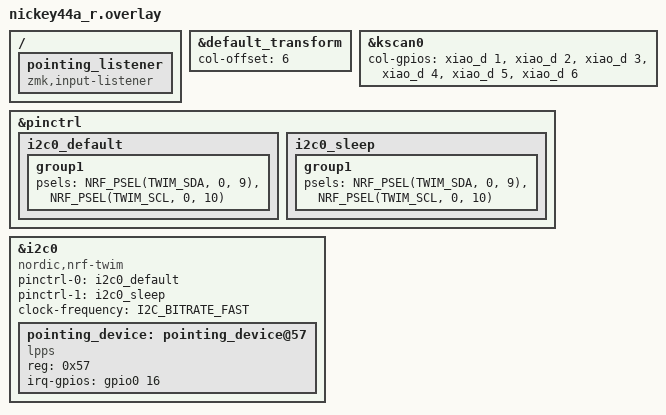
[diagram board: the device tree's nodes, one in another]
#include "nickey44a.dtsi"

&default_transform {
    col-offset = <6>;
};

&kscan0 {
        col-gpios
            = <&xiao_d 1 GPIO_ACTIVE_HIGH>
            , <&xiao_d 2 GPIO_ACTIVE_HIGH>
            , <&xiao_d 3 GPIO_ACTIVE_HIGH>
            , <&xiao_d 4 GPIO_ACTIVE_HIGH>
            , <&xiao_d 5 GPIO_ACTIVE_HIGH>
            , <&xiao_d 6 GPIO_ACTIVE_HIGH>
            ;
};

/ {
    pointing_listener: pointing_listener {
        compatible = "zmk,input-listener";
        status = "okay";
    };
};

&pinctrl {
    i2c0_default: i2c0_default {
        group1 {
            psels = <NRF_PSEL(TWIM_SDA, 0, 9)>,
                    <NRF_PSEL(TWIM_SCL, 0, 10)>;
        };
    };

    i2c0_sleep: i2c0_sleep {
        group1 {
            psels = <NRF_PSEL(TWIM_SDA, 0, 9)>,
                    <NRF_PSEL(TWIM_SCL, 0, 10)>;
        };
    };
};

&i2c0 {
    status = "okay";
    compatible = "nordic,nrf-twim";
    pinctrl-0 = <&i2c0_default>;
    pinctrl-1 = <&i2c0_sleep>;
    pinctrl-names = "default", "sleep";
    clock-frequency = <I2C_BITRATE_FAST>;

    pointing_device: pointing_device@57 {
        status = "okay";
        compatible = "lpps";
        reg = <0x57>;
        irq-gpios = <&gpio0 16 GPIO_PULL_UP>;
    };
};
